# ADuCM410 register map
Vendor: Analog Devices; Series: ADuCM410; File version: 1p0
CPU: CM33 r0p1, little endian, MPU, FPU, 3 interrupt priority bits
Registers are 32-bit, read-write, reset 0x0 unless marked. A register's access mark holds for its fields unless they carry their own. Offsets are from the block's base; [hi:lo] are bit positions; {n}, {i} and the like mark numbered series; 'fields as' and 'values as' point back to an identical list.

## ADC
Base 0x40068000
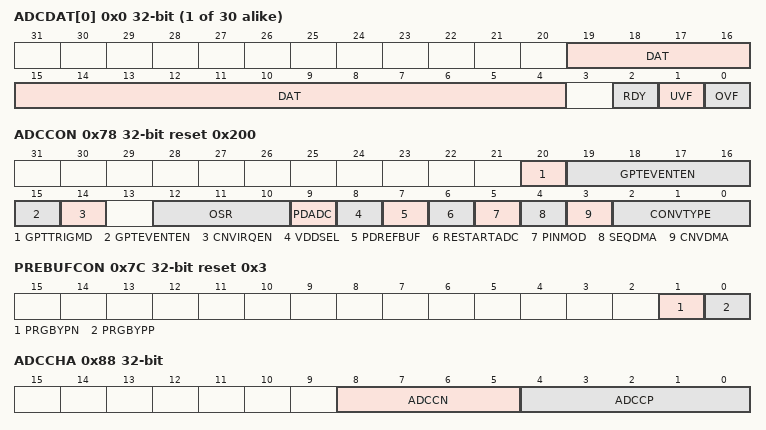
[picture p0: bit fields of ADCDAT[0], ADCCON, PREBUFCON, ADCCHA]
{0x0+4i} ADCDAT[{i}] (i=0..29) — ADCx Data and Flags
  [19:4] DAT ro — ADCx Data
  [2] RDY ro — Data Read Flag
    0=NORDY (Data is Not Ready or Has Been Read Out); 1=RDY (Data is Ready to Be Read)
  [1] UVF ro — Underflow Flag
    0=NUNF (Not Underflow); 1=UNF (Underflow)
  [0] OVF ro — Overflow Flag
    0=NOVF (Not Overflow); 1=OVF (Overflow)
0x78 ADCCON reset 0x200 — ADC Configuration
  [20] GPTTRIGMD — Mux Select GP Timer Trigger Mode
    0=MD0 (Two Timeout Events Trigger One Conversion); 1=MD1 (One Timeout Events Trigger One Conversion)
  [19:15] GPTEVENTEN range 0x00000000..0x0000001F — Enable GPT Event to Trigger Conversion
  [14] CNVIRQEN range 0x00000000..0x00000001 — Enable Conversion Interrupt Generation
  [12:10] OSR — Oversampling Ratio
    0=OSR_NS1 (Oversampling Disable); 1=Oversampling X2; 2=Oversampling X4; 3=Oversampling X8; 4=Oversampling X16; 5=OSR_NS32 (Oversampling X32); 6=OSR_NS64 (Oversampling Disable); 7=OSR_NS128 (Oversampling Disable)
  [9] PDADC — ADC Power Down
    0=ADCPU (Not Power Down ADC); 1=ADCPD (Power Down ADC)
  [8] VDDSEL — Select Whether Channel 29 is DVDD Channel or AVDD Channel
    0=DVDD (Channel 29 is Half of DVDD Channel); 1=AVSS (Channel 29 is AVSS Channel)
  [7] PDREFBUF — ADC Refbuf Power Down
    0=REFBUFPU (Normal Mode); 1=REFBUFPD (Power Down Reference Mode)
  [6] RESTARTADC — Restart ADC, Reset Analog Part of ADC
    0=ADCPU (Not Power Down ADC); 1=ADCPD (Power Down ADC)
  [5] PINMOD — PIN Conversion Mode Selection
    0=PIN_LVL (CNV is Controlled by PIN Level); 1=PIN_EDGE (CNV is Controlled by PIN Edge)
  [4] SEQDMA range 0x00000000..0x00000001 — DMA Request Enable for ADC Sequence Conversion
  [3] CNVDMA range 0x00000000..0x00000001 — DMA Request Enable for ADC Non-sequence Conversion
  [2:0] CONVTYPE — ADC Conversion Type Selection
    0=IDLE (No Conversion); 1=GPIO (ADC Controlled by GPIO Pin); 2=SINGL (Software Single Conversion); 3=CONT (Software Continue Conversion); 4=PLA (PLA Conversion); 5=GPT (GPT Triggered Conversion)
0x7C PREBUFCON reset 0x3 — Pre-charge Buffer Control
  [1] PRGBYPN range 0x00000000..0x00000001 — Bypass N Channel Pre_buf
  [0] PRGBYPP range 0x00000000..0x00000001 — Bypass P Channel Pre_buf
0x80 ADCCNVC reset 0x10 — ADC Conversion Cycle for Positive Input Channels
  [31:0] CNVC range 0x00000000..0xFFFFFFFF — CNV Frequency Configuration for Positive Channels
0x84 ADCCNVCSLOW reset 0x140 — ADC Conversion Cycle for Positive Input Channels
  [31:0] CNVCSLOW range 0x00000000..0xFFFFFFFF — CNV Frequency Configuration for 100KSPS Channels
0x88 ADCCHA — ADC Channel Select
  [8:5] ADCCN range 0x00000000..0x0000000F — ADC N Channel Selection
  [4:0] ADCCP — ADC P Channel Selection
    {v}=AIN{v} (Unknown) (v=0..15); {v}=PGA{v-16} (Unknown) (v=16..19); 20=TEMPSNS (Unknown); 21=AVDDDIV2 (Unknown); 22=IOVDD0DIV2 (Unknown); 23=IOVDD1 (Unknown); {v}=HVTIA{v-24} (Unknown) (v=24..28); 29=AVSS (Unknown)
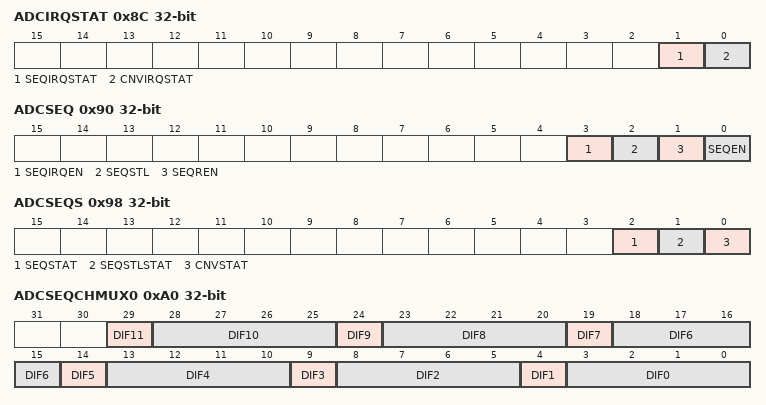
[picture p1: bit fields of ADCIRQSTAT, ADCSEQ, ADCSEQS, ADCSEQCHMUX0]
0x8C ADCIRQSTAT — ADC Interrupt Status
  [1] SEQIRQSTAT ro — Sequence Conversion IRQ Status
    0=IRQCLR (Interrupt Clear); 1=IRQSET (Interrupt Set)
  [0] CNVIRQSTAT ro — Single Conversion IRQ Status
    0=IRQCLR (Interrupt Clear); 1=IRQSET (Interrupt Set)
0x90 ADCSEQ — ADC Sequencer Control
  [3] SEQIRQEN range 0x00000000..0x00000001 — Enable Sequencer Interrupt Generation
  [2] SEQSTL — Sequence Stall
    0=SEQNSTALL (Running Sequence); 1=SEQSTALL (Stalling Sequence)
  [1] SEQREN wo range 0x00000000..0x00000001 — Sequence Restart
  [0] SEQEN wo range 0x00000000..0x00000001 — Sequence Enable
0x94 ADCSEQC — ADC Sequencer Configuration
  [7:0] SEQT range 0x00000000..0x000000FF — Repeat Sequence Interval
0x98 ADCSEQS — ADC Sequencer Status
  [2] SEQSTAT ro — Sequencer Status
    0=SEQNBUSY (Sequence is Idle); 1=SEQBUSY (Sequence is Busy)
  [1] SEQSTLSTAT ro — Stall Sequencer Status
    0=SEQNSTOP (Sequence Still Run); 1=SEQSTOP (Sequence Has Stalled)
  [0] CNVSTAT ro — ADC Conversion Idle/Busy Flag
    0=CNVIDLE (ADC Conversion is Idle); 1=CNVBUSY (ADC Conversion is Busy)
0x9C ADCSEQCH — ADC Sequencer Channel 0
  [29:0] SEQCH range 0x00000000..0x3FFFFFFF — Sequence Channel Selection
0xA0 ADCSEQCHMUX0 — ADC Sequencer Channel 1
  [29] DIF11 — When AIN11 is N Ch. P Ch. Mux Selection in Sequencer Mode
    0=REFN (Unknown); 1=REFP (Unknown)
  [28:25] DIF10 — When AIN10 is P Ch. N Ch. Mux Selection in Sequencer Mode
    0=REFN (Unknown); 1=REFP (Unknown); 2=AIN1 (Unknown); 3=AIN3 (Unknown); 4=AIN5 (Unknown); 5=AIN7 (Unknown); 6=AIN9 (Unknown); 7=AIN11 (Unknown); 8=AIN13 (Unknown); 9=AIN15 (Unknown)
  [24] DIF9 — When AIN9 is N Ch. P Ch. Mux Selection in Sequencer Mode
    0=REFN (Unknown); 1=REFP (Unknown)
  [23:20] DIF8 — When AIN8 is P Ch. N Ch. Mux Selection in Sequencer Mode
    values as DIF10
  [19] DIF7 — When AIN7 is N Ch. P Ch. Mux Selection in Sequencer Mode
    0=REFN (Unknown); 1=REFP (Unknown)
  [18:15] DIF6 — When AIN6 is P Ch. N Ch. Mux Selection in Sequencer Mode
    values as DIF10
  [14] DIF5 — When AIN5 is N Ch. P Ch. Mux Selection in Sequencer Mode
    0=REFN (Unknown); 1=REFP (Unknown)
  [13:10] DIF4 — When AIN4 is P Ch. N Ch. Mux Selection in Sequencer Mode
    values as DIF10
  [9] DIF3 — When AIN3 is N Ch. P Ch. Mux Selection in Sequencer Mode
    0=REFN (Unknown); 1=REFP (Unknown)
  [8:5] DIF2 — When AIN2 is P Ch. N Ch. Mux Selection in Sequencer Mode
    values as DIF10
  [4] DIF1 — When AIN1 is N Ch. P Ch. Mux Selection in Sequencer Mode
    0=REFN (Unknown); 1=REFP (Unknown)
  [3:0] DIF0 — When AIN0 is P Ch. N Ch. Mux Selection in Sequencer Mode
    values as DIF10
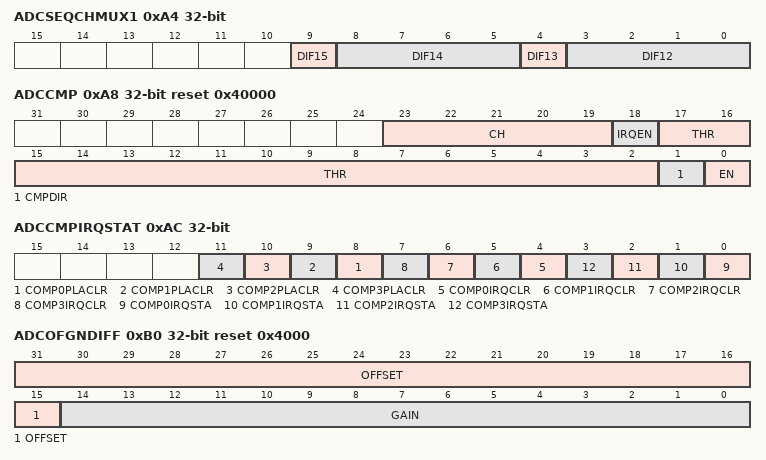
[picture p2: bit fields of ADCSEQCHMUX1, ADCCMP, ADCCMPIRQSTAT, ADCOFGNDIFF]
0xA4 ADCSEQCHMUX1 — ADC Sequencer Channel 1
  [9] DIF15 — When AIN15 is N Ch. P Ch. Mux Selection in Sequencer Mode
    0=REFN (Unknown); 1=REFP (Unknown)
  [8:5] DIF14 — When AIN14 is P Ch. N Ch. Mux Selection in Sequencer Mode
    values as ADCSEQCHMUX0.DIF10
  [4] DIF13 — When AIN13 is N Ch. P Ch. Mux Selection in Sequencer Mode
    0=REFN (Unknown); 1=REFP (Unknown)
  [3:0] DIF12 — When AIN12 is P Ch. N Ch. Mux Selection in Sequencer Mode
    values as ADCSEQCHMUX0.DIF10
0xA8 ADCCMP reset 0x40000 — Digital Comparator 0 Configuration
  [23:19] CH range 0x00000000..0x0000001F — Channel Index for Data Comparison
  [18] IRQEN range 0x00000000..0x00000001 — Enable IRQ Generation
  [17:2] THR range 0x00000000..0x0000FFFF — Compare Threshold
  [1] CMPDIR range 0x00000000..0x00000001 — Select Digital Comparator Direction
  [0] EN range 0x00000000..0x00000001 — Digital Comparator Enable
0xAC ADCCMPIRQSTAT — Digital Comparator Interrupt Status
  [n+8] COMP{n}PLACLR range 0x00000000..0x00000001 (n=0..3) — Comparator{n} to PLA Clear
  [n+4] COMP{n}IRQCLR range 0x00000000..0x00000001 (n=0..3) — Comparator{n} Interrupt Clear
  [n] COMP{n}IRQSTA ro (n=0..3) — Comparator{n} Interrupt Status
0xB0 ADCOFGNDIFF reset 0x4000 — ADC Offset Gain Differential Channel Error Correction
  [31:15] OFFSET range 0x00000000..0x0001FFFF — Offset Error Correction
  [14:0] GAIN range 0x00000000..0x00007FFF — Gain Error Correction
0xB4 ADCOFTEMP — ADC Offset Gain Temp Sensor Channel Error Correction
  [16:0] OFFSET range 0x00000000..0x0001FFFF — Offset Error Correction
0xB8 ADCGNTEMP reset 0x80000 — ADC Offset Gain Temp Sensor Channel Error Correction
  [19:0] GAIN range 0x00000000..0x000FFFFF — Gain Error Correction
{0xBC+4i} ADCOFGNPGA{i} reset 0x4000 (i=0..3) — ADC Offset Gain PGA{i} Channel Error Correction
  [14:0] GAIN range 0x00000000..0x00007FFF — Gain Error Correction
{0xCC+4i} ADCOFGNPGA{i}TIA reset 0x4000 (i=0..3) — ADC Offset Gain PGA{i} Channel Error Correction
  [14:0] GAIN range 0x00000000..0x00007FFF — Gain Error Correction
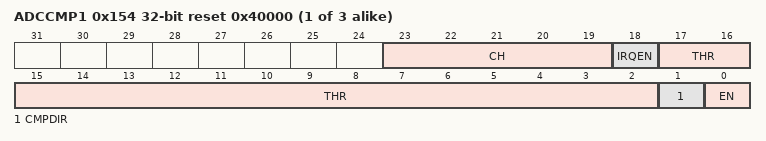
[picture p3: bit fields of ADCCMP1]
{0x150+4i} ADCCMP{i} reset 0x40000 (i=1..3) — Digital Comparator {i} Configuration
  fields as ADCCMP
